# ESP32-S3-ULP register map
Vendor: ESPRESSIF SYSTEMS (SHANGHAI) CO., LTD.; Series: RISC-V ULP; File version: 2
CPU: RV32IMC r0p0, little endian, no MPU, no FPU, 0 interrupt priority bits
Address unit: 32 bits
Registers are 32-bit, read-write, reset 0x0 unless marked. A register's access mark holds for its fields unless they carry their own. Offsets are from the block's base; [hi:lo] are bit positions; {n}, {i} and the like mark numbered series.

## RTC_I2C — Low-power I2C (Inter-Integrated Circuit) Controller
Base 0x0000EC00
0x00 SCL_LOW reset 0x100 — configure low scl period
  [19:0] PERIOD — time period that scl =0
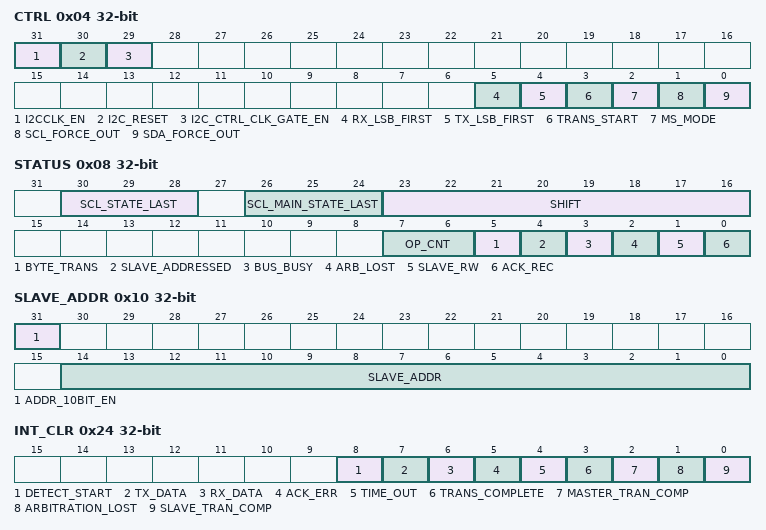
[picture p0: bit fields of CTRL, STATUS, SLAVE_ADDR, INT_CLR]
0x04 CTRL — configure i2c ctrl
  [31] I2CCLK_EN — rtc i2c reg clk gating
  [30] I2C_RESET — rtc i2c sw reset
  [29] I2C_CTRL_CLK_GATE_EN — configure i2c ctrl clk enable
  [5] RX_LSB_FIRST — receive lsb first
  [4] TX_LSB_FIRST — transit lsb first
  [3] TRANS_START — force start
  [2] MS_MODE — 1=master,0=slave
  [1] SCL_FORCE_OUT — 1=push pull,0=open drain
  [0] SDA_FORCE_OUT — 1=push pull,0=open drain
0x08 STATUS ro — get i2c status
  [30:28] SCL_STATE_LAST — scl last status
  [26:24] SCL_MAIN_STATE_LAST — i2c last main status
  [23:16] SHIFT — shifter content
  [7:6] OP_CNT — which operation is working
  [5] BYTE_TRANS — One byte transit done
  [4] SLAVE_ADDRESSED — slave reg sub address
  [3] BUS_BUSY — bus is busy
  [2] ARB_LOST — arbitration is lost
  [1] SLAVE_RW — slave read or write
  [0] ACK_REC — ack response
0x0C TO reset 0x10000 — configure time out
  [19:0] TIME_OUT — time out threshold
0x10 SLAVE_ADDR — configure slave id
  [31] ADDR_10BIT_EN — i2c 10bit mode enable
  [14:0] SLAVE_ADDR — slave address
0x14 SCL_HIGH reset 0x100 — configure high scl period
  [19:0] PERIOD — time period that scl = 1
0x18 SDA_DUTY reset 0x10 — configure sda duty
  [19:0] NUM — time period for SDA to toggle after SCL goes low
0x1C SCL_START_PERIOD reset 0x8 — configure scl start period
  [19:0] SCL_START_PERIOD — time period for SCL to toggle after I2C start is triggered
0x20 SCL_STOP_PERIOD reset 0x8 — configure scl stop period
  [19:0] SCL_STOP_PERIOD — time period for SCL to stop after I2C end is triggered
0x24 INT_CLR wo — interrupt clear register
  [8] DETECT_START write-1-clears — clear detect start interrupt
  [7] TX_DATA write-1-clears — clear transit load data complete interrupt
  [6] RX_DATA write-1-clears — clear receive data interrupt
  [5] ACK_ERR write-1-clears — clear ack error interrupt
  [4] TIME_OUT write-1-clears — clear time out interrupt
  [3] TRANS_COMPLETE write-1-clears — clear transit complete interrupt
  [2] MASTER_TRAN_COMP write-1-clears — clear master transit complete interrupt
  [1] ARBITRATION_LOST write-1-clears — clear arbitration lost interrupt
  [0] SLAVE_TRAN_COMP write-1-clears — clear slave transit complete interrupt
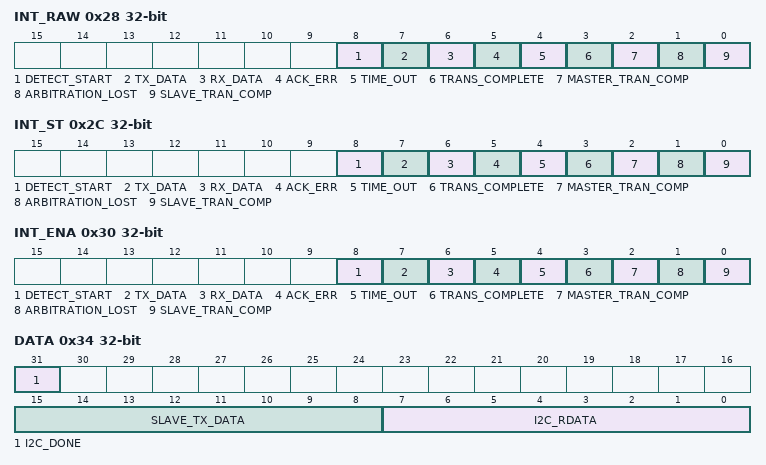
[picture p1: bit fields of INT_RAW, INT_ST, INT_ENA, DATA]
0x28 INT_RAW ro — interrupt raw register
  [8] DETECT_START — detect start interrupt raw
  [7] TX_DATA — transit data interrupt raw
  [6] RX_DATA — receive data interrupt raw
  [5] ACK_ERR — ack error interrupt raw
  [4] TIME_OUT — time out interrupt raw
  [3] TRANS_COMPLETE — transit complete interrupt raw
  [2] MASTER_TRAN_COMP — master transit complete interrupt raw
  [1] ARBITRATION_LOST — arbitration lost interrupt raw
  [0] SLAVE_TRAN_COMP — slave transit complete interrupt raw
0x2C INT_ST ro — interrupt state register
  [8] DETECT_START — detect start interrupt state
  [7] TX_DATA — transit data interrupt state
  [6] RX_DATA — receive data interrupt state
  [5] ACK_ERR — ack error interrupt state
  [4] TIME_OUT — time out interrupt state
  [3] TRANS_COMPLETE — transit complete interrupt state
  [2] MASTER_TRAN_COMP — master transit complete interrupt state
  [1] ARBITRATION_LOST — arbitration lost interrupt state
  [0] SLAVE_TRAN_COMP — slave transit complete interrupt state
0x30 INT_ENA — interrupt enable register
  [8] DETECT_START — enable detect start interrupt
  [7] TX_DATA — enable transit data interrupt
  [6] RX_DATA — enable receive data interrupt
  [5] ACK_ERR — enable eack error interrupt
  [4] TIME_OUT — enable time out interrupt
  [3] TRANS_COMPLETE — enable transit complete interrupt
  [2] MASTER_TRAN_COMP — enable master transit complete interrupt
  [1] ARBITRATION_LOST — enable arbitration lost interrupt
  [0] SLAVE_TRAN_COMP — enable slave transit complete interrupt
0x34 DATA access per field — get i2c data status
  [31] I2C_DONE ro
  [15:8] SLAVE_TX_DATA rw — data sent by slave
  [7:0] I2C_RDATA ro — data received
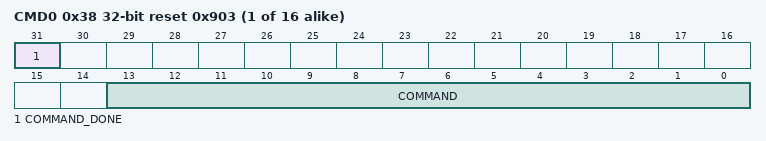
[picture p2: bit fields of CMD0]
{0x38+4i} CMD{i} (i=0..15) access per field reset 0x903 — I2C command{i} register
  [31] COMMAND_DONE ro — command0_done
  [13:0] COMMAND rw — command0
0xFC DATE reset 0x1905310 — version register
  [27:0] I2C_DATE — version
